# Port_C_5 register map
Vendor: Texas Instruments
Peripheral module from a debugger description file (folder msp430).
Registers are 16-bit, read-write, reset 0x0 unless marked. A register's access mark holds for its fields unless they carry their own. Offsets are as the file gives them; lines under a group give offsets from that group; [hi:lo] are bit positions; {n}, {i} and the like mark numbered series; 'fields as' and 'values as' point back to an identical list; <NAME> marks a mode.

## Port_C
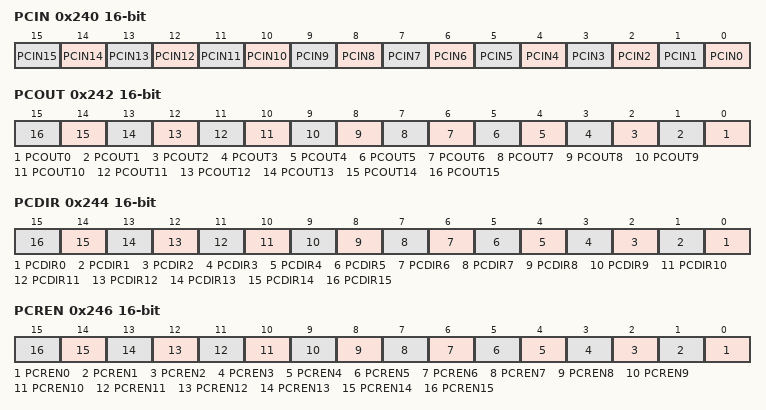
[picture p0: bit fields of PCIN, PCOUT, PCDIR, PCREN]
0x240 PCIN — Port C Input
  [n] PCIN{n} (n=0..15)
0x242 PCOUT — Port C Output
  [n] PCOUT{n} (n=0..15)
0x244 PCDIR — Port C Direction
  [n] PCDIR{n} (n=0..15)
0x246 PCREN — Port C Resistor Enable
  [n] PCREN{n} (n=0..15)
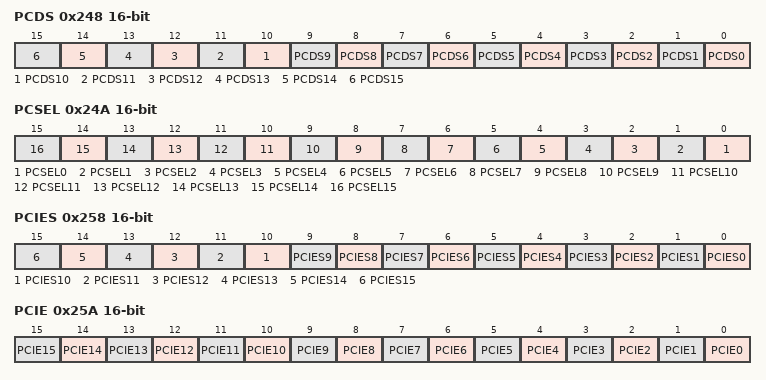
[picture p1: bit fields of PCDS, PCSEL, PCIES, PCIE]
0x248 PCDS — Port C Drive Strenght
  [n] PCDS{n} (n=0..15)
0x24A PCSEL — Port C Selection
  [n] PCSEL{n} (n=0..15)
0x258 PCIES — Port C Interrupt Edge Select
  [n] PCIES{n} (n=0..15)
0x25A PCIE — Port C Interrupt Enable
  [n] PCIE{n} (n=0..15)
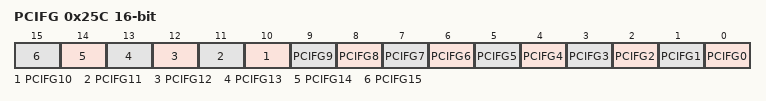
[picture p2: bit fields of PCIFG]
0x25C PCIFG — Port C Interrupt Flag
  [n] PCIFG{n} (n=0..15)
